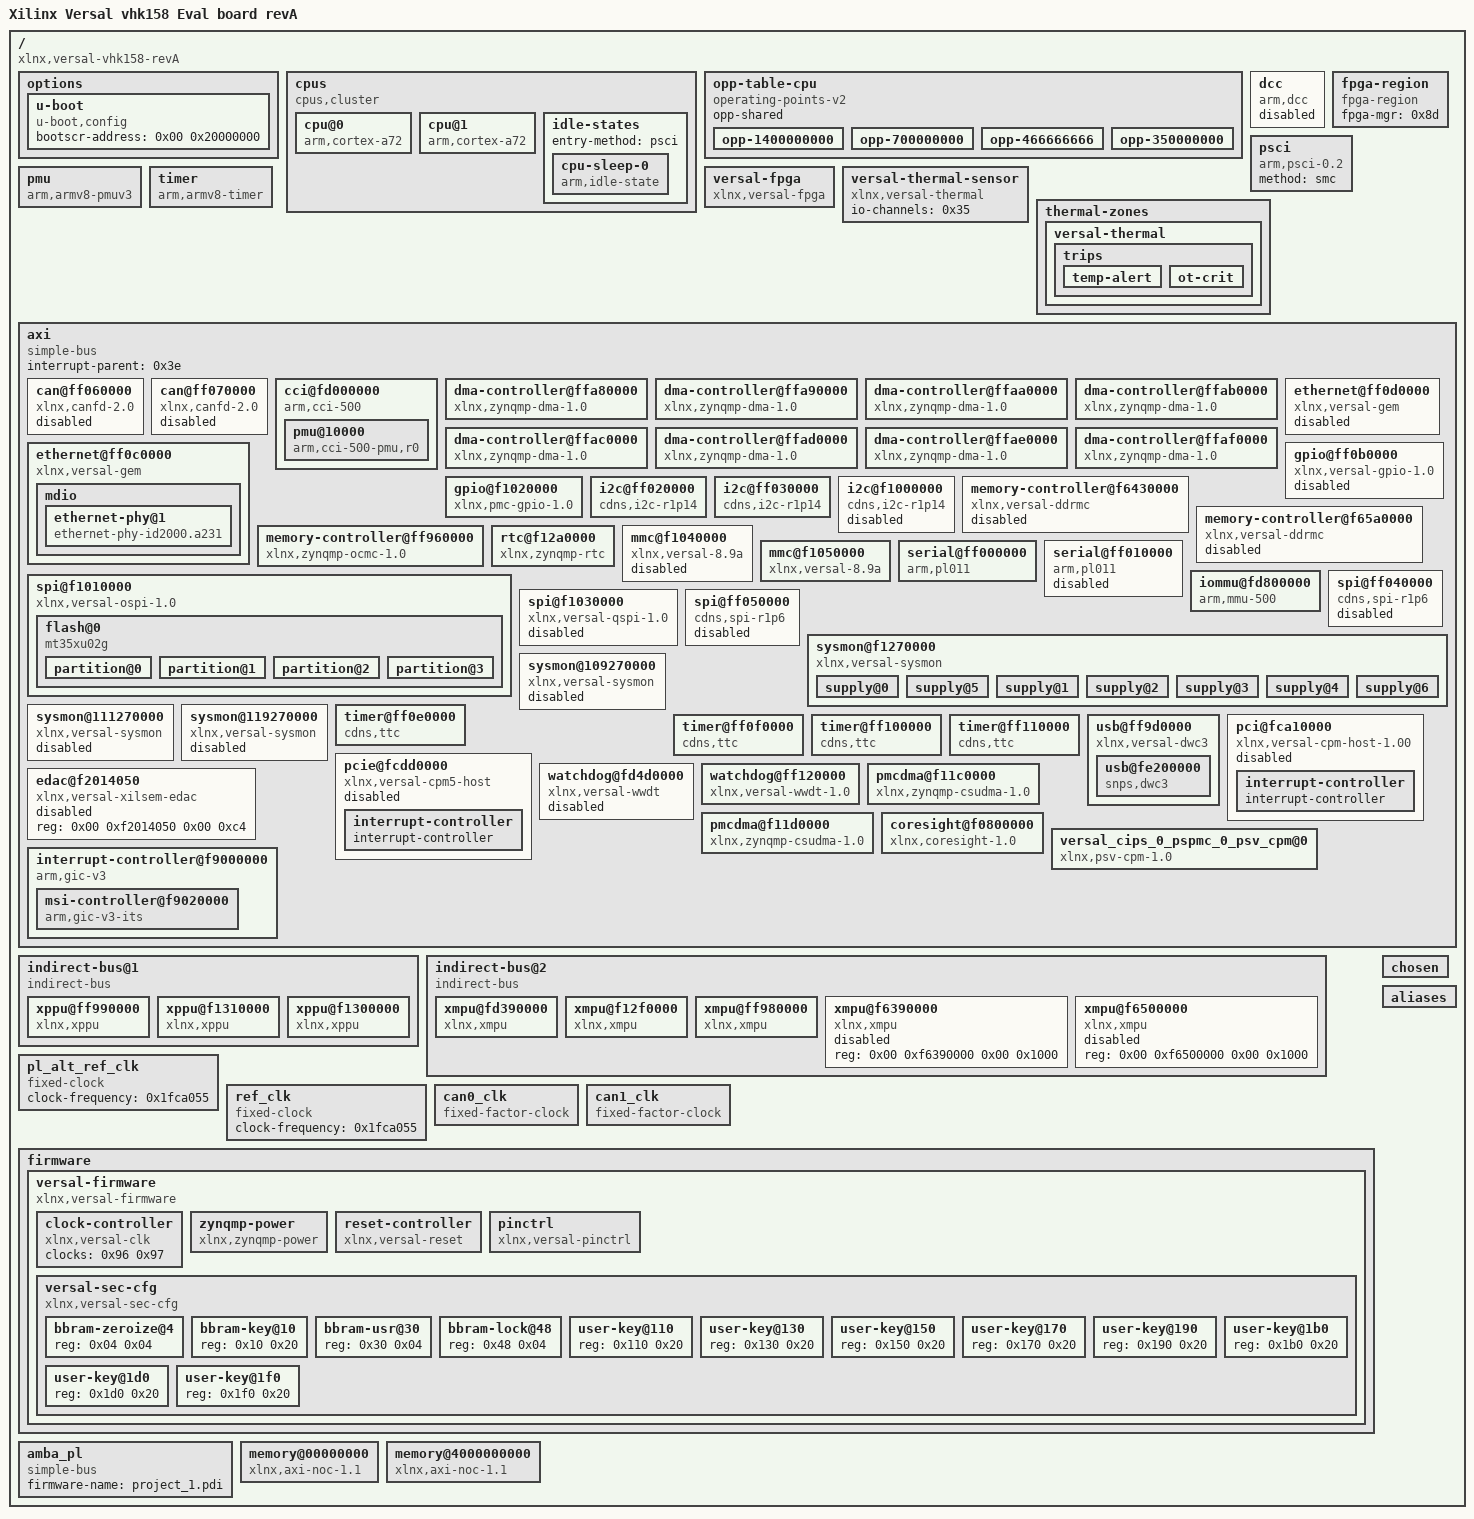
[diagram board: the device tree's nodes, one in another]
/dts-v1/;

/ {
	compatible = "xlnx,versal-vhk158-revA\0xlnx,versal-vhk158\0xlnx,versal";
	#address-cells = <0x02>;
	#size-cells = <0x02>;
	model = "Xilinx Versal vhk158 Eval board revA";
	board = "vhk158";
	device_id = "xcvh1582";
	slrcount = <0x02>;
	family = "Versal";

	options {

		u-boot {
			compatible = "u-boot,config";
			bootscr-address = <0x00 0x20000000>;
		};
	};

	cpus {
		#address-cells = <0x01>;
		#size-cells = <0x00>;
		compatible = "cpus,cluster";
		#ranges-address-cells = <0x02>;
		#ranges-size-cells = <0x02>;
		phandle = <0x98>;

		cpu@0 {
			compatible = "arm,cortex-a72\0arm,armv8";
			device_type = "cpu";
			enable-method = "psci";
			operating-points-v2 = <0x6f>;
			reg = <0x00>;
			cpu-idle-states = <0x70>;
			power-domains = <0x71 0x18110003>;
			clocks = <0x72 0x4d>;
			xlnx,timestamp-clk-freq = <0x5f5dd19>;
			xlnx,pss-ref-clk-freq = <0x1fc9f08>;
			stamp-frequency = <0x5f5dd19>;
			xlnx,ip-name = "psv_cortexa72";
			xlnx,cpu-clk-freq-hz = <0x5372172a>;
			cpu-frequency = <0x5372172a>;
			bus-handle = <0x01>;
			phandle = <0x99>;
		};

		cpu@1 {
			compatible = "arm,cortex-a72\0arm,armv8";
			device_type = "cpu";
			enable-method = "psci";
			operating-points-v2 = <0x6f>;
			reg = <0x01>;
			cpu-idle-states = <0x70>;
			power-domains = <0x71 0x18110004>;
			xlnx,timestamp-clk-freq = <0x5f5dd19>;
			xlnx,pss-ref-clk-freq = <0x1fc9f08>;
			stamp-frequency = <0x5f5dd19>;
			xlnx,ip-name = "psv_cortexa72";
			xlnx,cpu-clk-freq-hz = <0x5372172a>;
			cpu-frequency = <0x5372172a>;
			bus-handle = <0x01>;
			phandle = <0x9a>;
		};

		idle-states {
			entry-method = "psci";

			cpu-sleep-0 {
				compatible = "arm,idle-state";
				arm,psci-suspend-param = <0x40000000>;
				local-timer-stop;
				entry-latency-us = <0x12c>;
				exit-latency-us = <0x258>;
				min-residency-us = <0x2710>;
				phandle = <0x70>;
			};
		};
	};

	opp-table-cpu {
		compatible = "operating-points-v2";
		opp-shared;
		phandle = <0x6f>;

		opp-1400000000 {
			opp-hz = <0x00 0x53724e00>;
			clock-latency-ns = <0x7a120>;
			opp-microvolt = <0xf4240>;
		};

		opp-700000000 {
			opp-hz = <0x00 0x29b92700>;
			clock-latency-ns = <0x7a120>;
			opp-microvolt = <0xf4240>;
		};

		opp-466666666 {
			opp-hz = <0x00 0x1bd0c4aa>;
			clock-latency-ns = <0x7a120>;
			opp-microvolt = <0xf4240>;
		};

		opp-350000000 {
			opp-hz = <0x00 0x14dc9380>;
			clock-latency-ns = <0x7a120>;
			opp-microvolt = <0xf4240>;
		};
	};

	dcc {
		compatible = "arm,dcc";
		status = "disabled";
		bootph-all;
		phandle = <0xa3>;
	};

	fpga-region {
		compatible = "fpga-region";
		fpga-mgr = <0x8d>;
		#address-cells = <0x02>;
		#size-cells = <0x02>;
		phandle = <0xa4>;
	};

	psci {
		compatible = "arm,psci-0.2";
		method = "smc";
		phandle = <0xa5>;
	};

	pmu {
		compatible = "arm,armv8-pmuv3";
		interrupt-parent = <0x3e>;
		interrupts = <0x01 0x07 0x304>;
	};

	timer {
		compatible = "arm,armv8-timer";
		interrupt-parent = <0x3e>;
		interrupts = <0x01 0x0d 0x04 0x01 0x0e 0x04 0x01 0x0b 0x04 0x01 0x0a 0x04>;
		phandle = <0xa6>;
	};

	versal-fpga {
		compatible = "xlnx,versal-fpga";
		phandle = <0x8d>;
	};

	versal-thermal-sensor {
		compatible = "xlnx,versal-thermal";
		#thermal-sensor-cells = <0x00>;
		io-channels = <0x35>;
		io-channel-names = "sysmon-temp-channel";
		phandle = <0x8f>;
	};

	thermal-zones {

		versal-thermal {
			polling-delay-passive = <0xfa>;
			polling-delay = <0x3e8>;
			thermal-sensors = <0x8f>;
			phandle = <0xa7>;

			trips {

				temp-alert {
					temperature = <0x11170>;
					hysteresis = <0x00>;
					type = "passive";
					phandle = <0xa8>;
				};

				ot-crit {
					temperature = <0x1e848>;
					hysteresis = <0x00>;
					type = "critical";
					phandle = <0xa9>;
				};
			};
		};
	};

	axi {
		compatible = "simple-bus";
		#address-cells = <0x02>;
		#size-cells = <0x02>;
		ranges;
		interrupt-parent = <0x3e>;
		bootph-all;
		phandle = <0x01>;

		can@ff060000 {
			compatible = "xlnx,canfd-2.0";
			status = "disabled";
			reg = <0x00 0xff060000 0x00 0x6000>;
			interrupts = <0x00 0x14 0x04>;
			interrupt-parent = <0x3e>;
			clock-names = "can_clk\0s_axi_aclk";
			rx-fifo-depth = <0x40>;
			tx-mailbox-count = <0x20>;
			clocks = <0x90 0x72 0x52>;
			power-domains = <0x71 0x1822401f>;
			phandle = <0xaa>;
		};

		can@ff070000 {
			compatible = "xlnx,canfd-2.0";
			status = "disabled";
			reg = <0x00 0xff070000 0x00 0x6000>;
			interrupts = <0x00 0x15 0x04>;
			interrupt-parent = <0x3e>;
			clock-names = "can_clk\0s_axi_aclk";
			rx-fifo-depth = <0x40>;
			tx-mailbox-count = <0x20>;
			clocks = <0x91 0x72 0x52>;
			power-domains = <0x71 0x18224020>;
			phandle = <0xab>;
		};

		cci@fd000000 {
			compatible = "arm,cci-500";
			status = "okay";
			reg = <0x00 0xfd000000 0x00 0x10000>;
			ranges = <0x00 0x00 0xfd000000 0xa0000>;
			#address-cells = <0x01>;
			#size-cells = <0x01>;
			xlnx,ip-name = "psv_fpd_maincci";
			phandle = <0x40>;

			pmu@10000 {
				compatible = "arm,cci-500-pmu,r0";
				reg = <0x10000 0x90000>;
				interrupt-parent = <0x3e>;
				interrupts = <0x00 0x6a 0x04 0x00 0x6a 0x04 0x00 0x6a 0x04 0x00 0x6a 0x04 0x00 0x6a 0x04 0x00 0x6a 0x04 0x00 0x6a 0x04 0x00 0x6a 0x04>;
				phandle = <0xac>;
			};
		};

		dma-controller@ffa80000 {
			compatible = "xlnx,zynqmp-dma-1.0";
			status = "okay";
			reg = <0x00 0xffa80000 0x00 0x1000>;
			interrupts = <0x00 0x3c 0x04>;
			interrupt-parent = <0x3e>;
			clock-names = "clk_main\0clk_apb";
			xlnx,dma-type = <0x01>;
			#dma-cells = <0x01>;
			xlnx,bus-width = <0x40>;
			clocks = <0x72 0x51 0x72 0x52>;
			power-domains = <0x71 0x18224035>;
			xlnx,is-cache-coherent = <0x00>;
			xlnx,ip-name = "psv_adma";
			xlnx,dma-mode = <0x01>;
			phandle = <0x63>;
		};

		dma-controller@ffa90000 {
			compatible = "xlnx,zynqmp-dma-1.0";
			status = "okay";
			reg = <0x00 0xffa90000 0x00 0x1000>;
			interrupts = <0x00 0x3d 0x04>;
			interrupt-parent = <0x3e>;
			clock-names = "clk_main\0clk_apb";
			xlnx,dma-type = <0x01>;
			#dma-cells = <0x01>;
			xlnx,bus-width = <0x40>;
			clocks = <0x72 0x51 0x72 0x52>;
			power-domains = <0x71 0x18224036>;
			xlnx,is-cache-coherent = <0x00>;
			xlnx,ip-name = "psv_adma";
			xlnx,dma-mode = <0x01>;
			phandle = <0x64>;
		};

		dma-controller@ffaa0000 {
			compatible = "xlnx,zynqmp-dma-1.0";
			status = "okay";
			reg = <0x00 0xffaa0000 0x00 0x1000>;
			interrupts = <0x00 0x3e 0x04>;
			interrupt-parent = <0x3e>;
			clock-names = "clk_main\0clk_apb";
			xlnx,dma-type = <0x01>;
			#dma-cells = <0x01>;
			xlnx,bus-width = <0x40>;
			clocks = <0x72 0x51 0x72 0x52>;
			power-domains = <0x71 0x18224037>;
			xlnx,is-cache-coherent = <0x00>;
			xlnx,ip-name = "psv_adma";
			xlnx,dma-mode = <0x01>;
			phandle = <0x65>;
		};

		dma-controller@ffab0000 {
			compatible = "xlnx,zynqmp-dma-1.0";
			status = "okay";
			reg = <0x00 0xffab0000 0x00 0x1000>;
			interrupts = <0x00 0x3f 0x04>;
			interrupt-parent = <0x3e>;
			clock-names = "clk_main\0clk_apb";
			xlnx,dma-type = <0x01>;
			#dma-cells = <0x01>;
			xlnx,bus-width = <0x40>;
			clocks = <0x72 0x51 0x72 0x52>;
			power-domains = <0x71 0x18224038>;
			xlnx,is-cache-coherent = <0x00>;
			xlnx,ip-name = "psv_adma";
			xlnx,dma-mode = <0x01>;
			phandle = <0x66>;
		};

		dma-controller@ffac0000 {
			compatible = "xlnx,zynqmp-dma-1.0";
			status = "okay";
			reg = <0x00 0xffac0000 0x00 0x1000>;
			interrupts = <0x00 0x40 0x04>;
			interrupt-parent = <0x3e>;
			clock-names = "clk_main\0clk_apb";
			xlnx,dma-type = <0x01>;
			#dma-cells = <0x01>;
			xlnx,bus-width = <0x40>;
			clocks = <0x72 0x51 0x72 0x52>;
			power-domains = <0x71 0x18224039>;
			xlnx,is-cache-coherent = <0x00>;
			xlnx,ip-name = "psv_adma";
			xlnx,dma-mode = <0x01>;
			phandle = <0x67>;
		};

		dma-controller@ffad0000 {
			compatible = "xlnx,zynqmp-dma-1.0";
			status = "okay";
			reg = <0x00 0xffad0000 0x00 0x1000>;
			interrupts = <0x00 0x41 0x04>;
			interrupt-parent = <0x3e>;
			clock-names = "clk_main\0clk_apb";
			xlnx,dma-type = <0x01>;
			#dma-cells = <0x01>;
			xlnx,bus-width = <0x40>;
			clocks = <0x72 0x51 0x72 0x52>;
			power-domains = <0x71 0x1822403a>;
			xlnx,is-cache-coherent = <0x00>;
			xlnx,ip-name = "psv_adma";
			xlnx,dma-mode = <0x01>;
			phandle = <0x68>;
		};

		dma-controller@ffae0000 {
			compatible = "xlnx,zynqmp-dma-1.0";
			status = "okay";
			reg = <0x00 0xffae0000 0x00 0x1000>;
			interrupts = <0x00 0x42 0x04>;
			interrupt-parent = <0x3e>;
			clock-names = "clk_main\0clk_apb";
			xlnx,dma-type = <0x01>;
			#dma-cells = <0x01>;
			xlnx,bus-width = <0x40>;
			clocks = <0x72 0x51 0x72 0x52>;
			power-domains = <0x71 0x1822403b>;
			xlnx,is-cache-coherent = <0x00>;
			xlnx,ip-name = "psv_adma";
			xlnx,dma-mode = <0x01>;
			phandle = <0x69>;
		};

		dma-controller@ffaf0000 {
			compatible = "xlnx,zynqmp-dma-1.0";
			status = "okay";
			reg = <0x00 0xffaf0000 0x00 0x1000>;
			interrupts = <0x00 0x43 0x04>;
			interrupt-parent = <0x3e>;
			clock-names = "clk_main\0clk_apb";
			xlnx,dma-type = <0x01>;
			#dma-cells = <0x01>;
			xlnx,bus-width = <0x40>;
			clocks = <0x72 0x51 0x72 0x52>;
			power-domains = <0x71 0x1822403c>;
			xlnx,is-cache-coherent = <0x00>;
			xlnx,ip-name = "psv_adma";
			xlnx,dma-mode = <0x01>;
			phandle = <0x6a>;
		};

		ethernet@ff0c0000 {
			compatible = "xlnx,versal-gem\0cdns,gem";
			status = "okay";
			reg = <0x00 0xff0c0000 0x00 0x1000>;
			interrupts = <0x00 0x38 0x04 0x00 0x38 0x04>;
			interrupt-parent = <0x3e>;
			clock-names = "pclk\0hclk\0tx_clk\0rx_clk\0tsu_clk";
			#address-cells = <0x01>;
			#size-cells = <0x00>;
			clocks = <0x72 0x52 0x72 0x58 0x72 0x31 0x72 0x30 0x72 0x2b>;
			power-domains = <0x71 0x18224019>;
			xlnx,has-mdio = <0x01>;
			xlnx,is-cache-coherent = <0x00>;
			xlnx,gem-board-interface = "custom";
			phy-mode = "rgmii-id";
			xlnx,enet-slcr-1000mbps-div0 = <0x02>;
			xlnx,enet-slcr-10mbps-div0 = <0x64>;
			xlnx,enet-tsu-clk-freq-hz = <0xee6a8ba>;
			xlnx,ip-name = "psv_ethernet";
			xlnx,eth-mode = <0x01>;
			xlnx,enet-clk-freq-hz = <0x773545d>;
			xlnx,enet-slcr-100mbps-div0 = <0x0a>;
			local-mac-address = [ff ff ff ff ff ff];
			phy-handle = <0x92>;
			phandle = <0x52>;

			mdio {
				#address-cells = <0x01>;
				#size-cells = <0x00>;
				phandle = <0xad>;

				ethernet-phy@1 {
					#phy-cells = <0x01>;
					compatible = "ethernet-phy-id2000.a231";
					reg = <0x01>;
					ti,rx-internal-delay = <0x0b>;
					ti,tx-internal-delay = <0x0a>;
					ti,fifo-depth = <0x01>;
					ti,dp83867-rxctrl-strap-quirk;
					reset-assert-us = <0x64>;
					reset-deassert-us = <0x118>;
					reset-gpios = <0x27 0x30 0x01>;
					phandle = <0x92>;
				};
			};
		};

		ethernet@ff0d0000 {
			compatible = "xlnx,versal-gem\0cdns,gem";
			status = "disabled";
			reg = <0x00 0xff0d0000 0x00 0x1000>;
			interrupts = <0x00 0x3a 0x04 0x00 0x3a 0x04>;
			interrupt-parent = <0x3e>;
			clock-names = "pclk\0hclk\0tx_clk\0rx_clk\0tsu_clk";
			#address-cells = <0x01>;
			#size-cells = <0x00>;
			clocks = <0x72 0x52 0x72 0x59 0x72 0x33 0x72 0x32 0x72 0x2b>;
			power-domains = <0x71 0x1822401a>;
			phandle = <0xae>;
		};

		gpio@ff0b0000 {
			compatible = "xlnx,versal-gpio-1.0";
			status = "disabled";
			reg = <0x00 0xff0b0000 0x00 0x1000>;
			interrupts = <0x00 0x0d 0x04>;
			interrupt-parent = <0x3e>;
			#gpio-cells = <0x02>;
			gpio-controller;
			#interrupt-cells = <0x02>;
			interrupt-controller;
			clocks = <0x72 0x52>;
			power-domains = <0x71 0x18224023>;
			phandle = <0xaf>;
		};

		gpio@f1020000 {
			compatible = "xlnx,pmc-gpio-1.0";
			status = "okay";
			reg = <0x00 0xf1020000 0x00 0x1000>;
			interrupts = <0x00 0x7a 0x04>;
			interrupt-parent = <0x3e>;
			#gpio-cells = <0x02>;
			gpio-controller;
			#interrupt-cells = <0x02>;
			interrupt-controller;
			clocks = <0x72 0x3d>;
			power-domains = <0x71 0x1822402c>;
			xlnx,ip-name = "psv_pmc_gpio";
			phandle = <0x27>;
		};

		i2c@ff020000 {
			compatible = "cdns,i2c-r1p14";
			status = "okay";
			reg = <0x00 0xff020000 0x00 0x1000>;
			interrupts = <0x00 0x0e 0x04>;
			interrupt-parent = <0x3e>;
			clock-frequency = <0x186a0>;
			#address-cells = <0x01>;
			#size-cells = <0x00>;
			clocks = <0x72 0x62>;
			power-domains = <0x71 0x1822401d>;
			xlnx,clock-freq = <0x5f5dd19>;
			xlnx,i2c-clk-freq-hz = <0x5f5dd19>;
			xlnx,ip-name = "psv_i2c";
			xlnx,iic-board-interface = "custom";
			phandle = <0x4e>;
		};

		i2c@ff030000 {
			compatible = "cdns,i2c-r1p14";
			status = "okay";
			reg = <0x00 0xff030000 0x00 0x1000>;
			interrupts = <0x00 0x0f 0x04>;
			interrupt-parent = <0x3e>;
			clock-frequency = <0x186a0>;
			#address-cells = <0x01>;
			#size-cells = <0x00>;
			clocks = <0x72 0x63>;
			power-domains = <0x71 0x1822401e>;
			xlnx,clock-freq = <0x5f5dd19>;
			xlnx,i2c-clk-freq-hz = <0x5f5dd19>;
			xlnx,ip-name = "psv_i2c";
			xlnx,iic-board-interface = "custom";
			phandle = <0x4f>;
		};

		i2c@f1000000 {
			compatible = "cdns,i2c-r1p14";
			status = "disabled";
			reg = <0x00 0xf1000000 0x00 0x1000>;
			interrupts = <0x00 0x7b 0x04>;
			interrupt-parent = <0x3e>;
			clock-frequency = <0x186a0>;
			#address-cells = <0x01>;
			#size-cells = <0x00>;
			clocks = <0x72 0x3e>;
			power-domains = <0x71 0x1822402d>;
			phandle = <0xb0>;
		};

		memory-controller@f6430000 {
			compatible = "xlnx,versal-ddrmc";
			status = "disabled";
			reg = <0x00 0xf6430000 0x00 0x2000 0x00 0xf6380000 0x00 0x20000>;
			reg-names = "base\0noc";
			interrupts = <0x00 0x93 0x04>;
			interrupt-parent = <0x3e>;
			phandle = <0xb3>;
		};

		memory-controller@f65a0000 {
			compatible = "xlnx,versal-ddrmc";
			status = "disabled";
			reg = <0x00 0xf65a0000 0x00 0x2000 0x00 0xf64f0000 0x00 0x20000>;
			reg-names = "base\0noc";
			interrupts = <0x00 0x93 0x04>;
			interrupt-parent = <0x3e>;
			phandle = <0xb4>;
		};

		memory-controller@ff960000 {
			compatible = "xlnx,zynqmp-ocmc-1.0";
			reg = <0x00 0xff960000 0x00 0x1000>;
			interrupts = <0x00 0x0a 0x04>;
			interrupt-parent = <0x3e>;
			phandle = <0xb5>;
		};

		rtc@f12a0000 {
			compatible = "xlnx,zynqmp-rtc";
			status = "okay";
			reg = <0x00 0xf12a0000 0x00 0x100>;
			interrupt-names = "alarm\0sec";
			interrupts = <0x00 0x8e 0x04 0x00 0x8f 0x04>;
			interrupt-parent = <0x3e>;
			calibration = <0x7fff>;
			power-domains = <0x71 0x18224034>;
			xlnx,ip-name = "psv_pmc_rtc";
			phandle = <0x36>;
		};

		mmc@f1040000 {
			compatible = "xlnx,versal-8.9a\0arasan,sdhci-8.9a";
			status = "disabled";
			reg = <0x00 0xf1040000 0x00 0x10000>;
			interrupts = <0x00 0x7e 0x04>;
			interrupt-parent = <0x3e>;
			clock-names = "clk_xin\0clk_ahb\0gate";
			#clock-cells = <0x01>;
			clock-output-names = "clk_out_sd0\0clk_in_sd0";
			clocks = <0x72 0x3b 0x72 0x52 0x72 0x4a>;
			power-domains = <0x71 0x1822402e>;
			phandle = <0xb6>;
		};

		mmc@f1050000 {
			compatible = "xlnx,versal-8.9a\0arasan,sdhci-8.9a";
			status = "okay";
			reg = <0x00 0xf1050000 0x00 0x10000>;
			interrupts = <0x00 0x80 0x04>;
			interrupt-parent = <0x3e>;
			clock-names = "clk_xin\0clk_ahb\0gate";
			#clock-cells = <0x01>;
			clock-output-names = "clk_out_sd1\0clk_in_sd1";
			clocks = <0x72 0x3c 0x72 0x52 0x72 0x4a>;
			power-domains = <0x71 0x1822402f>;
			xlnx,sd-board-interface = "custom";
			xlnx,is-cache-coherent = <0x00>;
			xlnx,clk-50-ddr-otap-dly = <0x03>;
			xlnx,clk-50-sdr-itap-dly = <0x25>;
			xlnx,has-emio = <0x00>;
			clock-frequency = <0xbebba31>;
			xlnx,clk-100-sdr-otap-dly = <0x03>;
			xlnx,mio-bank = <0x01>;
			xlnx,ip-name = "psv_pmc_sd";
			xlnx,bus-width = <0x08>;
			xlnx,card-detect = <0x01>;
			xlnx,has-wp = <0x00>;
			xlnx,has-cd = <0x01>;
			xlnx,slot-type = <0x04>;
			xlnx,clk-50-sdr-otap-dly = <0x04>;
			xlnx,clk-50-ddr-itap-dly = <0x2a>;
			xlnx,has-power = <0x01>;
			xlnx,clk-200-sdr-otap-dly = <0x02>;
			xlnx,sdio-clk-freq-hz = <0xbebba31>;
			xlnx,write-protect = <0x00>;
			no-1-8-v;
			phandle = <0x28>;
		};

		serial@ff000000 {
			compatible = "arm,pl011\0arm,primecell";
			status = "okay";
			reg = <0x00 0xff000000 0x00 0x1000>;
			interrupts = <0x00 0x12 0x04>;
			interrupt-parent = <0x3e>;
			reg-io-width = <0x04>;
			clock-names = "uartclk\0apb_pclk";
			bootph-all;
			clocks = <0x72 0x5c 0x72 0x52>;
			power-domains = <0x71 0x18224021>;
			xlnx,has-modem = <0x00>;
			xlnx,uart-clk-freq-hz = <0x5f5dd19>;
			port-number = <0x00>;
			xlnx,ip-name = "psv_sbsauart";
			xlnx,uart-board-interface = "custom";
			xlnx,baudrate = <0x1c200>;
			cts-override;
			u-boot,dm-pre-reloc;
			xlnx,clock-freq = <0x5f5dd19>;
			phandle = <0x4d>;
		};

		serial@ff010000 {
			compatible = "arm,pl011\0arm,primecell";
			status = "disabled";
			reg = <0x00 0xff010000 0x00 0x1000>;
			interrupts = <0x00 0x13 0x04>;
			interrupt-parent = <0x3e>;
			reg-io-width = <0x04>;
			clock-names = "uartclk\0apb_pclk";
			bootph-all;
			clocks = <0x72 0x5d 0x72 0x52>;
			power-domains = <0x71 0x18224022>;
			phandle = <0xb7>;
		};

		iommu@fd800000 {
			compatible = "arm,mmu-500";
			status = "okay";
			reg = <0x00 0xfd800000 0x00 0x40000>;
			stream-match-mask = <0x7c00>;
			#iommu-cells = <0x01>;
			#global-interrupts = <0x01>;
			interrupts = <0x00 0x6b 0x04 0x00 0x6b 0x04 0x00 0x6b 0x04 0x00 0x6b 0x04 0x00 0x6b 0x04 0x00 0x6b 0x04 0x00 0x6b 0x04 0x00 0x6b 0x04 0x00 0x6b 0x04 0x00 0x6b 0x04 0x00 0x6b 0x04 0x00 0x6b 0x04 0x00 0x6b 0x04 0x00 0x6b 0x04 0x00 0x6b 0x04 0x00 0x6b 0x04 0x00 0x6b 0x04 0x00 0x6b 0x04 0x00 0x6b 0x04 0x00 0x6b 0x04 0x00 0x6b 0x04 0x00 0x6b 0x04 0x00 0x6b 0x04 0x00 0x6b 0x04 0x00 0x6b 0x04 0x00 0x6b 0x04 0x00 0x6b 0x04 0x00 0x6b 0x04 0x00 0x6b 0x04 0x00 0x6b 0x04 0x00 0x6b 0x04 0x00 0x6b 0x04 0x00 0x6b 0x04>;
			interrupt-parent = <0x3e>;
			xlnx,ip-name = "psv_fpd_smmutcu";
			phandle = <0x4b>;
		};

		spi@f1010000 {
			compatible = "xlnx,versal-ospi-1.0\0cdns,qspi-nor";
			status = "okay";
			reg = <0x00 0xf1010000 0x00 0x10000 0x00 0xc0000000 0x00 0x20000000>;
			interrupts = <0x00 0x7c 0x04>;
			interrupt-parent = <0x3e>;
			cdns,fifo-depth = <0x100>;
			cdns,fifo-width = <0x04>;
			cdns,is-dma = <0x01>;
			cdns,trigger-address = <0xc0000000>;
			#address-cells = <0x01>;
			#size-cells = <0x00>;
			clocks = <0x72 0x3a>;
			power-domains = <0x71 0x1822402a>;
			reset-names = "qspi";
			resets = <0x93 0xc10402e>;
			is-stacked = <0x00>;
			xlnx,is-cache-coherent = <0x00>;
			xlnx,clock-freq = <0xbebba31>;
			xlnx,ip-name = "psv_pmc_ospi";
			xlnx,ospi-clk-freq-hz = <0xbebba31>;
			is-dual = <0x00>;
			xlnx,ospi-mode = <0x00>;
			bus-num = <0x02>;
			num-cs = <0x01>;
			phandle = <0x26>;

			flash@0 {
				compatible = "mt35xu02g\0micron,m25p80\0jedec,spi-nor";
				reg = <0x00>;
				#address-cells = <0x01>;
				#size-cells = <0x01>;
				cdns,read-delay = <0x00>;
				cdns,tshsl-ns = <0x00>;
				cdns,tsd2d-ns = <0x00>;
				cdns,tchsh-ns = <0x01>;
				cdns,tslch-ns = <0x01>;
				spi-tx-bus-width = <0x08>;
				spi-rx-bus-width = <0x08>;
				spi-max-frequency = <0x1312d00>;
				no-wp;
				reset-gpios = <0x27 0x0c 0x01>;
				phandle = <0x02>;

				partition@0 {
					label = "spi0-boot";
					reg = <0x00 0x40000>;
				};

				partition@1 {
					label = "spi0-bootenv";
					reg = <0x40000 0x20000>;
				};

				partition@2 {
					label = "spi0-config";
					reg = <0x60000 0x20000>;
				};

				partition@3 {
					label = "spi0-kernel";
					reg = <0x80000 0xc00000>;
				};
			};
		};

		spi@f1030000 {
			compatible = "xlnx,versal-qspi-1.0";
			status = "disabled";
			reg = <0x00 0xf1030000 0x00 0x1000>;
			interrupts = <0x00 0x7d 0x04>;
			interrupt-parent = <0x3e>;
			clock-names = "ref_clk\0pclk";
			#address-cells = <0x01>;
			#size-cells = <0x00>;
			clocks = <0x72 0x39 0x72 0x52>;
			power-domains = <0x71 0x1822402b>;
			phandle = <0xb8>;
		};

		spi@ff040000 {
			compatible = "cdns,spi-r1p6";
			status = "disabled";
			reg = <0x00 0xff040000 0x00 0x1000>;
			interrupts = <0x00 0x10 0x04>;
			interrupt-parent = <0x3e>;
			clock-names = "ref_clk\0pclk";
			#address-cells = <0x01>;
			#size-cells = <0x00>;
			clocks = <0x72 0x5e 0x72 0x52>;
			power-domains = <0x71 0x1822401b>;
			phandle = <0xb9>;
		};

		spi@ff050000 {
			compatible = "cdns,spi-r1p6";
			status = "disabled";
			reg = <0x00 0xff050000 0x00 0x1000>;
			interrupts = <0x00 0x11 0x04>;
			interrupt-parent = <0x3e>;
			clock-names = "ref_clk\0pclk";
			#address-cells = <0x01>;
			#size-cells = <0x00>;
			clocks = <0x72 0x5f 0x72 0x52>;
			power-domains = <0x71 0x1822401c>;
			phandle = <0xba>;
		};

		sysmon@f1270000 {
			compatible = "xlnx,versal-sysmon";
			#io-channel-cells = <0x00>;
			reg = <0x00 0xf1270000 0x00 0x4000>;
			interrupts = <0x00 0x90 0x04>;
			xlnx,numchannels = [07];
			#address-cells = <0x02>;
			#size-cells = <0x02>;
			xlnx,nodeid = <0x18224055>;
			xlnx,sat-63-desc = "PS , FPD , satellite";
			xlnx,sat-1-desc = "PMC , system , ADC";
			xlnx,sat-17-x = <0x351d>;
			xlnx,sat-9-x = <0x6e0c>;
			xlnx,sat-20-desc = "HBM , Satellite , (right)";
			xlnx,sat-19-desc = "VNOC , satellite";
			xlnx,sat-17-y = <0x3efd>;
			xlnx,sat-9-y = <0x4ebb>;
			xlnx,sat-22-x = <0x20df>;
			xlnx,meas-0-root-id = <0x00>;
			xlnx,sat-22-y = <0x4af0>;
			xlnx,meas-1-root-id = <0x05>;
			xlnx,ip-name = "psv_pmc_sysmon";
			xlnx,meas-2-root-id = <0x01>;
			xlnx,sat-16-desc = "HBM , Satellite , (left)";
			xlnx,meas-2-slr-number = <0x00>;
			xlnx,meas-3-root-id = <0x02>;
			xlnx,sat-9-desc = "Clocking , column , satellite";
			xlnx,sat-26-x = <0xe8e>;
			xlnx,meas-4-root-id = <0x03>;
			xlnx,sat-28-desc = "Clocking , column , satellite";
			xlnx,sat-26-y = <0x5480>;
			xlnx,meas-5-root-id = <0x04>;
			xlnx,sat-10-x = <0x6e0c>;
			xlnx,sat-64-x = <0x4a3>;
			xlnx,sat-2-x = <0x4a3>;
			xlnx,meas-6-root-id = <0x06>;
			xlnx,sat-10-y = <0x488c>;
			xlnx,sat-64-y = <0xe49>;
			xlnx,sat-2-y = <0x3c2b>;
			xlnx,sat-13-desc = "VNOC , satellite";
			xlnx,sat-6-desc = "HBM , Satellite , (right)";
			xlnx,sat-14-x = <0x495b>;
			xlnx,sat-6-x = <0x5eb2>;
			xlnx,sat-25-desc = "Clocking , column , satellite";
			xlnx,sat-14-y = <0x4af0>;
			xlnx,sat-6-y = <0x6f0e>;
			xlnx,sat-10-desc = "Clocking , column , satellite";
			xlnx,sat-18-x = <0x351d>;
			xlnx,sat-3-desc = "VNOC , satellite";
			xlnx,sat-18-y = <0x4af0>;
			xlnx,meas-5-slr-number = <0x00>;
			xlnx,sat-22-desc = "VNOC , satellite";
			xlnx,sat-23-x = <0x20df>;
			xlnx,meas-0-slr-number = <0x00>;
			xlnx,sat-23-y = <0x56e4>;
			xlnx,sat-18-desc = "VNOC , satellite";
			xlnx,sat-27-x = <0xe8e>;
			xlnx,sat-27-y = <0x4ebb>;
			xlnx,sat-11-x = <0x6e0c>;
			xlnx,sat-3-x = <0x5d99>;
			xlnx,sat-11-y = <0x42c8>;
			xlnx,sat-3-y = <0x3efd>;
			status = "okay";
			xlnx,sat-15-desc = "VNOC , satellite";
			xlnx,sat-15-x = <0x495b>;
			xlnx,sat-8-desc = "Clocking , column , satellite";
			xlnx,sat-7-x = <0x6e0c>;
			xlnx,sat-15-y = <0x56e4>;
			xlnx,sat-7-y = <0x5aaf>;
			xlnx,sat-27-desc = "Clocking , column , satellite";
			xlnx,meas-3-slr-number = <0x00>;
			xlnx,sat-20-x = <0x3379>;
			xlnx,sat-19-x = <0x351d>;
			xlnx,sat-12-desc = "Clocking , column , satellite";
			xlnx,sat-20-y = <0x6f0e>;
			xlnx,sat-19-y = <0x56e4>;
			xlnx,sat-5-desc = "VNOC , satellite";
			xlnx,sat-24-desc = "HBM , Satellite , (left)";
			xlnx,sat-24-x = <0x1de0>;
			xlnx,sat-24-y = <0x6f0e>;
			xlnx,sat-64-desc = "PS , LPD , satellite";
			xlnx,sat-2-desc = "PMC , user , ADC";
			xlnx,sat-28-x = <0xe8e>;
			xlnx,sat-21-desc = "VNOC , satellite";
			xlnx,sat-28-y = <0x488c>;
			xlnx,meas-6-slr-number = <0x00>;
			xlnx,sat-12-x = <0x6e0c>;
			xlnx,sat-4-x = <0x5d99>;
			xlnx,sat-12-y = <0x3c99>;
			xlnx,sat-4-y = <0x4af0>;
			xlnx,meas-1-slr-number = <0x00>;
			xlnx,sat-16-x = <0x4918>;
			xlnx,sat-17-desc = "VNOC , satellite";
			xlnx,sat-8-x = <0x6e0c>;
			xlnx,sat-16-y = <0x6f0e>;
			xlnx,sat-8-y = <0x5480>;
			xlnx,meas-0 = "VCCAUX";
			xlnx,meas-1 = "VCC_SOC";
			xlnx,sat-21-x = <0x20df>;
			xlnx,meas-2 = "VCCAUX_PMC";
			xlnx,sat-21-y = <0x3efd>;
			xlnx,meas-3 = "VCC_PMC";
			xlnx,sat-14-desc = "VNOC , satellite";
			xlnx,meas-4 = "VCC_PSFP";
			xlnx,sat-7-desc = "Clocking , column , satellite";
			xlnx,meas-5 = "VCC_PSLP";
			xlnx,sat-26-desc = "Clocking , column , satellite";
			xlnx,sat-25-x = <0xe8e>;
			xlnx,meas-6 = "VP_VN";
			xlnx,sat-25-y = <0x5aaf>;
			xlnx,sat-63-x = <0x4a3>;
			xlnx,sat-1-x = <0x4a3>;
			xlnx,meas-4-slr-number = <0x00>;
			xlnx,sat-11-desc = "Clocking , column , satellite";
			xlnx,sat-63-y = <0xe49>;
			xlnx,sat-1-y = <0x3c2b>;
			xlnx,sat-4-desc = "VNOC , satellite";
			xlnx,sat-23-desc = "VNOC , satellite";
			xlnx,sat-13-x = <0x495b>;
			xlnx,sat-5-x = <0x5d99>;
			xlnx,sat-13-y = <0x3efd>;
			xlnx,sat-5-y = <0x56e4>;
			phandle = <0x35>;

			supply@0 {
				reg = <0x00>;
				xlnx,name = "vccaux";
			};

			supply@5 {
				reg = <0x05>;
				xlnx,name = "vcc_soc";
			};

			supply@1 {
				reg = <0x01>;
				xlnx,name = "vccaux_pmc";
			};

			supply@2 {
				reg = <0x02>;
				xlnx,name = "vcc_pmc";
			};

			supply@3 {
				reg = <0x03>;
				xlnx,name = "vcc_psfp";
			};

			supply@4 {
				reg = <0x04>;
				xlnx,name = "vcc_pslp";
			};

			supply@6 {
				reg = <0x06>;
				xlnx,name = "vp_vn";
			};
		};

		sysmon@109270000 {
			compatible = "xlnx,versal-sysmon";
			status = "disabled";
			reg = <0x01 0x9270000 0x00 0x4000>;
			xlnx,numchannels = [00];
			#address-cells = <0x01>;
			#size-cells = <0x00>;
			xlnx,nodeid = <0x18225055>;
			phandle = <0xbb>;
		};

		sysmon@111270000 {
			compatible = "xlnx,versal-sysmon";
			status = "disabled";
			reg = <0x01 0x11270000 0x00 0x4000>;
			xlnx,numchannels = [00];
			#address-cells = <0x01>;
			#size-cells = <0x00>;
			xlnx,nodeid = <0x18226055>;
			phandle = <0xbc>;
		};

		sysmon@119270000 {
			compatible = "xlnx,versal-sysmon";
			status = "disabled";
			reg = <0x01 0x19270000 0x00 0x4000>;
			xlnx,numchannels = [00];
			#address-cells = <0x01>;
			#size-cells = <0x00>;
			xlnx,nodeid = <0x18227055>;
			phandle = <0xbd>;
		};

		timer@ff0e0000 {
			compatible = "cdns,ttc";
			status = "okay";
			interrupts = <0x00 0x25 0x04 0x00 0x26 0x04 0x00 0x27 0x04>;
			interrupt-parent = <0x3e>;
			reg = <0x00 0xff0e0000 0x00 0x1000>;
			timer-width = <0x20>;
			clocks = <0x72 0x27 0x72 0x52>;
			power-domains = <0x71 0x18224024>;
			xlnx,ttc-clk2-clksrc = <0x00>;
			xlnx,ip-name = "psv_ttc";
			xlnx,ttc-clk1-clksrc = <0x00>;
			xlnx,ttc-clk0-freq-hz = <0x8f0cba9>;
			xlnx,ttc-clk1-freq-hz = <0x8f0cba9>;
			xlnx,ttc-clk2-freq-hz = <0x8f0cba9>;
			xlnx,ttc-board-interface = "custom";
			xlnx,clock-freq = <0x8f0cba9>;
			xlnx,ttc-clk0-clksrc = <0x00>;
			phandle = <0x53>;
		};

		timer@ff0f0000 {
			compatible = "cdns,ttc";
			status = "okay";
			interrupts = <0x00 0x28 0x04 0x00 0x29 0x04 0x00 0x2a 0x04>;
			interrupt-parent = <0x3e>;
			reg = <0x00 0xff0f0000 0x00 0x1000>;
			timer-width = <0x20>;
			clocks = <0x72 0x28 0x72 0x52>;
			power-domains = <0x71 0x18224025>;
			xlnx,ttc-clk2-clksrc = <0x00>;
			xlnx,ip-name = "psv_ttc";
			xlnx,ttc-clk1-clksrc = <0x00>;
			xlnx,ttc-clk0-freq-hz = <0x8f0cba9>;
			xlnx,ttc-clk1-freq-hz = <0x8f0cba9>;
			xlnx,ttc-clk2-freq-hz = <0x8f0cba9>;
			xlnx,ttc-board-interface = "custom";
			xlnx,clock-freq = <0x8f0cba9>;
			xlnx,ttc-clk0-clksrc = <0x00>;
			phandle = <0x54>;
		};

		timer@ff100000 {
			compatible = "cdns,ttc";
			status = "okay";
			interrupts = <0x00 0x2b 0x04 0x00 0x2c 0x04 0x00 0x2d 0x04>;
			interrupt-parent = <0x3e>;
			reg = <0x00 0xff100000 0x00 0x1000>;
			timer-width = <0x20>;
			clocks = <0x72 0x29 0x72 0x52>;
			power-domains = <0x71 0x18224026>;
			xlnx,ttc-clk2-clksrc = <0x00>;
			xlnx,ip-name = "psv_ttc";
			xlnx,ttc-clk1-clksrc = <0x00>;
			xlnx,ttc-clk0-freq-hz = <0x8f0cba9>;
			xlnx,ttc-clk1-freq-hz = <0x8f0cba9>;
			xlnx,ttc-clk2-freq-hz = <0x8f0cba9>;
			xlnx,ttc-board-interface = "custom";
			xlnx,clock-freq = <0x8f0cba9>;
			xlnx,ttc-clk0-clksrc = <0x00>;
			phandle = <0x55>;
		};

		timer@ff110000 {
			compatible = "cdns,ttc";
			status = "okay";
			interrupts = <0x00 0x2e 0x04 0x00 0x2f 0x04 0x00 0x30 0x04>;
			interrupt-parent = <0x3e>;
			reg = <0x00 0xff110000 0x00 0x1000>;
			timer-width = <0x20>;
			clocks = <0x72 0x2a 0x72 0x52>;
			power-domains = <0x71 0x18224027>;
			xlnx,ttc-clk2-clksrc = <0x00>;
			xlnx,ip-name = "psv_ttc";
			xlnx,ttc-clk1-clksrc = <0x00>;
			xlnx,ttc-clk0-freq-hz = <0x8f0cba9>;
			xlnx,ttc-clk1-freq-hz = <0x8f0cba9>;
			xlnx,ttc-clk2-freq-hz = <0x8f0cba9>;
			xlnx,ttc-board-interface = "custom";
			xlnx,clock-freq = <0x8f0cba9>;
			xlnx,ttc-clk0-clksrc = <0x00>;
			phandle = <0x56>;
		};

		usb@ff9d0000 {
			compatible = "xlnx,versal-dwc3";
			status = "okay";
			reg = <0x00 0xff9d0000 0x00 0x100>;
			clock-names = "bus_clk\0ref_clk";
			ranges;
			#address-cells = <0x02>;
			#size-cells = <0x02>;
			clocks = <0x72 0x5b 0x72 0x68>;
			power-domains = <0x71 0x18224018>;
			resets = <0x93 0xc104036>;
			xlnx,ip-name = "psv_usb";
			phandle = <0x62>;

			usb@fe200000 {
				compatible = "snps,dwc3";
				status = "okay";
				reg = <0x00 0xfe200000 0x00 0x10000>;
				interrupt-names = "host\0peripheral\0otg\0wakeup";
				interrupts = <0x00 0x16 0x04 0x00 0x16 0x04 0x00 0x1a 0x04 0x00 0x4a 0x04>;
				snps,dis_u2_susphy_quirk;
				snps,dis_u3_susphy_quirk;
				snps,quirk-frame-length-adjustment = <0x20>;
				clock-names = "ref";
				clocks = <0x72 0x5b>;
				xlnx,is-cache-coherent = <0x00>;
				xlnx,ip-name = "psv_usb_xhci";
				dr_mode = "host";
				maximum-speed = "high-speed";
				snps,usb3_lpm_capable;
				phandle = <0x4c>;
			};
		};

		pci@fca10000 {
			device_type = "pci";
			#address-cells = <0x03>;
			#interrupt-cells = <0x01>;
			#size-cells = <0x02>;
			compatible = "xlnx,versal-cpm-host-1.00";
			status = "disabled";
			interrupt-map = <0x00 0x00 0x00 0x01 0x94 0x00 0x00 0x00 0x00 0x02 0x94 0x01 0x00 0x00 0x00 0x03 0x94 0x02 0x00 0x00 0x00 0x04 0x94 0x03>;
			interrupt-map-mask = <0x00 0x00 0x00 0x07>;
			interrupt-names = "misc";
			interrupts = <0x00 0x48 0x04>;
			xlnx,csr-slcr = <0x06 0x00>;
			xlnx,num-of-bars = <0x02>;
			xlnx,port-type = <0x01>;
			interrupt-parent = <0x3e>;
			bus-range = <0x00 0xff>;
			ranges = <0x2000000 0x00 0xe0010000 0x00 0xe0010000 0x00 0x10000000 0x43000000 0x80 0x00 0x80 0x00 0x00 0x80000000>;
			msi-map = <0x00 0x05 0x00 0x10000>;
			reg = <0x06 0x00 0x00 0x1000000 0x00 0xfca10000 0x00 0x1000>;
			reg-names = "cfg\0cpm_slcr";
			phandle = <0xbe>;

			interrupt-controller {
				#address-cells = <0x00>;
				#interrupt-cells = <0x01>;
				interrupt-controller;
				phandle = <0x94>;
			};
		};

		pcie@fcdd0000 {
			device_type = "pci";
			#address-cells = <0x03>;
			#interrupt-cells = <0x01>;
			#size-cells = <0x02>;
			compatible = "xlnx,versal-cpm5-host";
			status = "disabled";
			interrupt-map = <0x00 0x00 0x00 0x01 0x95 0x00 0x00 0x00 0x00 0x02 0x95 0x01 0x00 0x00 0x00 0x03 0x95 0x02 0x00 0x00 0x00 0x04 0x95 0x03>;
			interrupt-map-mask = <0x00 0x00 0x00 0x07>;
			interrupt-names = "misc";
			interrupts = <0x00 0x48 0x04>;
			xlnx,csr-slcr = <0xfce20000>;
			xlnx,num-of-bars = <0x02>;
			xlnx,port-type = <0x01>;
			interrupt-parent = <0x3e>;
			bus-range = <0x00 0xff>;
			ranges = <0x2000000 0x00 0xe0000000 0x00 0xe0000000 0x00 0x10000000 0x43000000 0x80 0x00 0x80 0x00 0x00 0x80000000>;
			msi-map = <0x00 0x05 0x00 0x10000>;
			reg = <0x06 0x00 0x00 0x1000000 0x00 0xfcdd0000 0x00 0x1000 0x00 0xfce20000 0x00 0x1000000>;
			reg-names = "cfg\0cpm_slcr\0cpm_csr";
			phandle = <0xbf>;

			interrupt-controller {
				#address-cells = <0x00>;
				#interrupt-cells = <0x01>;
				interrupt-controller;
				phandle = <0x95>;
			};
		};

		watchdog@fd4d0000 {
			compatible = "xlnx,versal-wwdt";
			status = "disabled";
			reg = <0x00 0xfd4d0000 0x00 0x10000>;
			interrupt-names = "wdt\0wwdt_reset_pending\0gwdt\0gwdt_reset_pending";
			interrupts = <0x00 0x64 0x01 0x00 0x6d 0x01 0x00 0x6c 0x01 0x00 0x6e 0x01>;
			interrupt-parent = <0x3e>;
			timeout-sec = <0x1e>;
			clocks = <0x72 0x4c>;
			power-domains = <0x71 0x18224029>;
			phandle = <0xc0>;
		};

		watchdog@ff120000 {
			compatible = "xlnx,versal-wwdt-1.0\0xlnx,versal-wwdt";
			status = "okay";
			reg = <0x00 0xff120000 0x00 0x10000>;
			interrupt-parent = <0x3e>;
			interrupt-names = "wdt\0wwdt_reset_pending\0gwdt\0gwdt_reset_pending";
			interrupts = <0x00 0x31 0x01 0x00 0x45 0x01 0x00 0x46 0x04 0x00 0x47 0x04>;
			timeout-sec = <0x1e>;
			clocks = <0x72 0x52>;
			power-domains = <0x71 0x18224028>;
			xlnx,winwdt-example = <0x01>;
			xlnx,ip-name = "psv_wwdt";
			xlnx,wdt-clk-freq-hz = <0x5f5e100>;
			phandle = <0x57>;
		};

		edac@f2014050 {
			compatible = "xlnx,versal-xilsem-edac";
			status = "disabled";
			reg = <0x00 0xf2014050 0x00 0xc4>;
			phandle = <0xc1>;
		};

		pmcdma@f11c0000 {
			status = "okay";
			compatible = "xlnx,zynqmp-csudma-1.0";
			interrupt-parent = <0x3e>;
			interrupts = <0x00 0x83 0x04>;
			reg = <0x00 0xf11c0000 0x00 0x10000>;
			xlnx,dma-type = <0x01>;
			xlnx,ip-name = "psv_pmc_dma";
			phandle = <0x2a>;
		};

		pmcdma@f11d0000 {
			status = "okay";
			compatible = "xlnx,zynqmp-csudma-1.0";
			interrupt-parent = <0x3e>;
			interrupts = <0x00 0x84 0x04>;
			reg = <0x00 0xf11d0000 0x00 0x10000>;
			xlnx,dma-type = <0x02>;
			xlnx,ip-name = "psv_pmc_dma";
			phandle = <0x2b>;
		};

		coresight@f0800000 {
			compatible = "xlnx,coresight-1.0";
			status = "okay";
			reg = <0x00 0xf0800000 0x00 0x10000>;
			xlnx,ip-name = "psv_coresight";
			phandle = <0x0d>;
		};

		versal_cips_0_pspmc_0_psv_cpm@0 {
			compatible = "xlnx,psv-cpm-1.0";
			status = "okay";
			xlnx,ip-name = "psv_cpm";
			reg = <0x00 0xfc000000 0x00 0x1000000>;
			phandle = <0x3f>;
		};

		interrupt-controller@f9000000 {
			phandle = <0x3e>;
			xlnx,ip-name = "psv_acpu_gic";
			xlnx,apu-gic-its-ctl = <0xf9020000>;
			status = "okay";
			interrupts = <0x01 0x09 0x04>;
			interrupt-parent = <0x3e>;
			interrupt-controller;
			reg = <0x00 0xf9000000 0x00 0x80000 0x00 0xf9080000 0x00 0x80000>;
			ranges;
			#size-cells = <0x02>;
			#address-cells = <0x02>;
			#interrupt-cells = <0x03>;
			compatible = "arm,gic-v3";

			msi-controller@f9020000 {
				phandle = <0x05>;
				reg = <0x00 0xf9020000 0x00 0x20000>;
				#msi-cells = <0x01>;
				msi-controller;
				status = "okay";
				compatible = "arm,gic-v3-its";
			};
		};
	};

	indirect-bus@1 {
		compatible = "indirect-bus";
		#address-cells = <0x02>;
		#size-cells = <0x02>;
		phandle = <0x12e>;

		xppu@ff990000 {
			compatible = "xlnx,xppu";
			#firewall-cells = <0x00>;
			reg = <0x00 0xff990000 0x00 0x2000>;
			status = "okay";
			xlnx,ip-name = "psv_lpd_xppu";
			phandle = <0x5f>;
		};

		xppu@f1310000 {
			compatible = "xlnx,xppu";
			#firewall-cells = <0x00>;
			reg = <0x00 0xf1310000 0x00 0x2000>;
			status = "okay";
			xlnx,ip-name = "psv_pmc_xppu";
			phandle = <0x3b>;
		};

		xppu@f1300000 {
			compatible = "xlnx,xppu";
			#firewall-cells = <0x00>;
			reg = <0x00 0xf1300000 0x00 0x2000>;
			status = "okay";
			xlnx,ip-name = "psv_pmc_xppu_npi";
			phandle = <0x3a>;
		};
	};

	indirect-bus@2 {
		compatible = "indirect-bus";
		#address-cells = <0x02>;
		#size-cells = <0x02>;
		phandle = <0x12f>;

		xmpu@fd390000 {
			compatible = "xlnx,xmpu";
			#firewall-cells = <0x00>;
			reg = <0x00 0xfd390000 0x00 0x1000>;
			status = "okay";
			xlnx,ip-name = "psv_fpd_slave_xmpu";
			phandle = <0x44>;
		};

		xmpu@f12f0000 {
			compatible = "xlnx,xmpu";
			#firewall-cells = <0x00>;
			reg = <0x00 0xf12f0000 0x00 0x1000>;
			status = "okay";
			xlnx,ip-name = "psv_pmc_xmpu";
			phandle = <0x39>;
		};

		xmpu@ff980000 {
			compatible = "xlnx,xmpu";
			#firewall-cells = <0x00>;
			reg = <0x00 0xff980000 0x00 0x1000>;
			status = "okay";
			xlnx,ip-name = "psv_ocm_xmpu";
			phandle = <0x5e>;
		};

		xmpu@f6390000 {
			compatible = "xlnx,xmpu";
			#firewall-cells = <0x00>;
			reg = <0x00 0xf6390000 0x00 0x1000>;
			status = "disabled";
			phandle = <0x132>;
		};

		xmpu@f6500000 {
			compatible = "xlnx,xmpu";
			#firewall-cells = <0x00>;
			reg = <0x00 0xf6500000 0x00 0x1000>;
			status = "disabled";
			phandle = <0x133>;
		};
	};

	pl_alt_ref_clk {
		bootph-all;
		compatible = "fixed-clock";
		#clock-cells = <0x00>;
		clock-frequency = <0x1fca055>;
		phandle = <0x97>;
	};

	ref_clk {
		bootph-all;
		compatible = "fixed-clock";
		#clock-cells = <0x00>;
		clock-frequency = <0x1fca055>;
		phandle = <0x96>;
	};

	can0_clk {
		#clock-cells = <0x00>;
		compatible = "fixed-factor-clock";
		clocks = <0x72 0x60>;
		clock-div = <0x02>;
		clock-mult = <0x01>;
		phandle = <0x90>;
	};

	can1_clk {
		#clock-cells = <0x00>;
		compatible = "fixed-factor-clock";
		clocks = <0x72 0x61>;
		clock-div = <0x02>;
		clock-mult = <0x01>;
		phandle = <0x91>;
	};

	firmware {

		versal-firmware {
			compatible = "xlnx,versal-firmware";
			interrupt-parent = <0x3e>;
			bootph-all;
			method = "smc";
			#power-domain-cells = <0x01>;
			phandle = <0x71>;

			clock-controller {
				bootph-all;
				#clock-cells = <0x01>;
				compatible = "xlnx,versal-clk";
				clocks = <0x96 0x97>;
				clock-names = "ref_clk\0pl_alt_ref_clk";
				phandle = <0x72>;
			};

			zynqmp-power {
				compatible = "xlnx,zynqmp-power";
				phandle = <0x134>;
			};

			reset-controller {
				compatible = "xlnx,versal-reset";
				#reset-cells = <0x01>;
				phandle = <0x93>;
			};

			pinctrl {
				compatible = "xlnx,versal-pinctrl";
				phandle = <0x135>;
			};

			versal-sec-cfg {
				compatible = "xlnx,versal-sec-cfg";
				#address-cells = <0x01>;
				#size-cells = <0x01>;
				phandle = <0x136>;

				bbram-zeroize@4 {
					reg = <0x04 0x04>;
					phandle = <0x137>;
				};

				bbram-key@10 {
					reg = <0x10 0x20>;
					phandle = <0x138>;
				};

				bbram-usr@30 {
					reg = <0x30 0x04>;
					phandle = <0x139>;
				};

				bbram-lock@48 {
					reg = <0x48 0x04>;
					phandle = <0x13a>;
				};

				user-key@110 {
					reg = <0x110 0x20>;
					phandle = <0x13b>;
				};

				user-key@130 {
					reg = <0x130 0x20>;
					phandle = <0x13c>;
				};

				user-key@150 {
					reg = <0x150 0x20>;
					phandle = <0x13d>;
				};

				user-key@170 {
					reg = <0x170 0x20>;
					phandle = <0x13e>;
				};

				user-key@190 {
					reg = <0x190 0x20>;
					phandle = <0x13f>;
				};

				user-key@1b0 {
					reg = <0x1b0 0x20>;
					phandle = <0x140>;
				};

				user-key@1d0 {
					reg = <0x1d0 0x20>;
					phandle = <0x141>;
				};

				user-key@1f0 {
					reg = <0x1f0 0x20>;
					phandle = <0x142>;
				};
			};
		};
	};

	amba_pl {
		ranges;
		compatible = "simple-bus";
		#address-cells = <0x02>;
		#size-cells = <0x02>;
		firmware-name = "project_1.pdi";
		phandle = <0x143>;
	};

	memory@00000000 {
		compatible = "xlnx,axi-noc-1.1";
		xlnx,ip-name = "axi_noc";
		device_type = "memory";
		reg = <0x00 0x00 0x00 0x80000000 0x08 0x00 0x07 0x80000000>;
		memory_type = "memory";
		phandle = <0x03>;
	};

	memory@4000000000 {
		compatible = "xlnx,axi-noc-1.1";
		xlnx,ip-name = "axi_noc";
		device_type = "memory";
		reg = <0x40 0x00 0x00 0x40000000 0x40 0x40000000 0x00 0x40000000 0x40 0x80000000 0x00 0x40000000 0x40 0xc0000000 0x00 0x40000000 0x41 0x00 0x00 0x40000000 0x41 0x40000000 0x00 0x40000000 0x41 0x80000000 0x00 0x40000000 0x41 0xc0000000 0x00 0x40000000 0x42 0x00 0x00 0x40000000 0x42 0x40000000 0x00 0x40000000 0x42 0x80000000 0x00 0x40000000 0x42 0xc0000000 0x00 0x40000000 0x43 0x00 0x00 0x40000000 0x43 0x40000000 0x00 0x40000000 0x43 0x80000000 0x00 0x40000000 0x43 0xc0000000 0x00 0x40000000 0x44 0x00 0x00 0x40000000 0x44 0x40000000 0x00 0x40000000 0x44 0x80000000 0x00 0x40000000 0x44 0xc0000000 0x00 0x40000000 0x45 0x00 0x00 0x40000000 0x45 0x40000000 0x00 0x40000000 0x45 0x80000000 0x00 0x40000000 0x45 0xc0000000 0x00 0x40000000 0x46 0x00 0x00 0x40000000 0x46 0x40000000 0x00 0x40000000 0x46 0x80000000 0x00 0x40000000 0x46 0xc0000000 0x00 0x40000000 0x47 0x00 0x00 0x40000000 0x47 0x40000000 0x00 0x40000000 0x47 0x80000000 0x00 0x40000000 0x47 0xc0000000 0x00 0x40000000>;
		memory_type = "memory";
		phandle = <0x04>;
	};

	chosen {
		stdout-path = "serial0:115200n8";
		bootargs = "console=ttyAMA0 earlycon=pl011,mmio32,0xFF000000,115200n8 root=/dev/ram0 rw init_fatal_sh=1";
	};

	aliases {
		serial0 = "/axi/serial@ff000000";
		serial1 = "/axi/coresight@f0800000";
		i2c0 = "/axi/i2c@ff020000";
		i2c1 = "/axi/i2c@ff030000";
		ethernet0 = "/axi/ethernet@ff0c0000";
		serial2 = "/dcc";
		mmc0 = "/axi/mmc@f1050000";
		spi0 = "/axi/spi@f1010000";
		usb0 = "/axi/usb@ff9d0000";
		rtc0 = "/axi/rtc@f12a0000";
	};

	__symbols__ {
		cpus_a72 = "/cpus-a72@0";
		psv_cortexa72_0 = "/cpus-a72@0/cpu@0";
		psv_cortexa72_1 = "/cpus-a72@0/cpu@1";
		CPU_SLEEP_0 = "/cpus-a72@0/idle-states/cpu-sleep-0";
		cpu_opp_table = "/opp-table-cpu";
		dcc = "/dcc";
		fpga = "/fpga-region";
		psci = "/psci";
		timer = "/timer";
		versal_fpga = "/versal-fpga";
		sensor0 = "/versal-thermal-sensor";
		versal_thermal = "/thermal-zones/versal-thermal";
		temp_alert = "/thermal-zones/versal-thermal/trips/temp-alert";
		ot_crit = "/thermal-zones/versal-thermal/trips/ot-crit";
		amba_apu = "/apu-bus";
		gic_its = "/axi/interrupt-controller@f9000000/msi-controller@f9020000";
		amba = "/axi";
		imux = "/axi/interrupt-multiplex";
		can0 = "/axi/can@ff060000";
		can1 = "/axi/can@ff070000";
		cci = "/axi/cci@fd000000";
		cci_pmu = "/axi/cci@fd000000/pmu@10000";
		lpd_dma_chan0 = "/axi/dma-controller@ffa80000";
		lpd_dma_chan1 = "/axi/dma-controller@ffa90000";
		lpd_dma_chan2 = "/axi/dma-controller@ffaa0000";
		lpd_dma_chan3 = "/axi/dma-controller@ffab0000";
		lpd_dma_chan4 = "/axi/dma-controller@ffac0000";
		lpd_dma_chan5 = "/axi/dma-controller@ffad0000";
		lpd_dma_chan6 = "/axi/dma-controller@ffae0000";
		lpd_dma_chan7 = "/axi/dma-controller@ffaf0000";
		gem0 = "/axi/ethernet@ff0c0000";
		mdio = "/axi/ethernet@ff0c0000/mdio";
		phy1 = "/axi/ethernet@ff0c0000/mdio/ethernet-phy@1";
		gem1 = "/axi/ethernet@ff0d0000";
		gpio0 = "/axi/gpio@ff0b0000";
		gpio1 = "/axi/gpio@f1020000";
		i2c0 = "/axi/i2c@ff020000";
		i2c1 = "/axi/i2c@ff030000";
		i2c2 = "/axi/i2c@f1000000";
		mc2 = "/axi/memory-controller@f6430000";
		mc3 = "/axi/memory-controller@f65a0000";
		ocm = "/axi/memory-controller@ff960000";
		rtc = "/axi/rtc@f12a0000";
		sdhci0 = "/axi/mmc@f1040000";
		sdhci1 = "/axi/mmc@f1050000";
		serial0 = "/axi/serial@ff000000";
		serial1 = "/axi/serial@ff010000";
		smmu = "/axi/iommu@fd800000";
		ospi = "/axi/spi@f1010000";
		qspi = "/axi/spi@f1030000";
		spi0 = "/axi/spi@ff040000";
		spi1 = "/axi/spi@ff050000";
		sysmon0 = "/axi/sysmon@f1270000";
		sysmon1 = "/axi/sysmon@109270000";
		sysmon2 = "/axi/sysmon@111270000";
		sysmon3 = "/axi/sysmon@119270000";
		ttc0 = "/axi/timer@ff0e0000";
		ttc1 = "/axi/timer@ff0f0000";
		ttc2 = "/axi/timer@ff100000";
		ttc3 = "/axi/timer@ff110000";
		usb0 = "/axi/usb@ff9d0000";
		dwc3_0 = "/axi/usb@ff9d0000/usb@fe200000";
		cpm_pciea = "/axi/pci@fca10000";
		pcie_intc_0 = "/axi/pci@fca10000/interrupt-controller";
		cpm5_pcie = "/axi/pcie@fcdd0000";
		pcie_intc_2 = "/axi/pcie@fcdd0000/interrupt-controller";
		watchdog = "/axi/watchdog@fd4d0000";
		watchdog1 = "/axi/watchdog@ff120000";
		xilsem_edac = "/axi/edac@f2014050";
		dma0 = "/axi/pmcdma@f11c0000";
		dma1 = "/axi/pmcdma@f11d0000";
		coresight = "/axi/coresight@f0800000";
		versal_cips_0_pspmc_0_psv_cpm = "/axi/versal_cips_0_pspmc_0_psv_cpm@0";
		amba_xppu = "/indirect-bus@1";
		lpd_xppu = "/indirect-bus@1/xppu@ff990000";
		pmc_xppu = "/indirect-bus@1/xppu@f1310000";
		pmc_xppu_npi = "/indirect-bus@1/xppu@f1300000";
		amba_xmpu = "/indirect-bus@2";
		fpd_xmpu = "/indirect-bus@2/xmpu@fd390000";
		pmc_xmpu = "/indirect-bus@2/xmpu@f12f0000";
		ocm_xmpu = "/indirect-bus@2/xmpu@ff980000";
		ddrmc_xmpu_2 = "/indirect-bus@2/xmpu@f6390000";
		ddrmc_xmpu_3 = "/indirect-bus@2/xmpu@f6500000";
		pl_alt_ref_clk = "/pl_alt_ref_clk";
		ref_clk = "/ref_clk";
		can0_clk = "/can0_clk";
		can1_clk = "/can1_clk";
		versal_firmware = "/firmware/versal-firmware";
		versal_clk = "/firmware/versal-firmware/clock-controller";
		zynqmp_power = "/firmware/versal-firmware/zynqmp-power";
		versal_reset = "/firmware/versal-firmware/reset-controller";
		pinctrl0 = "/firmware/versal-firmware/pinctrl";
		versal_sec_cfg = "/firmware/versal-firmware/versal-sec-cfg";
		bbram_zeroize = "/firmware/versal-firmware/versal-sec-cfg/bbram-zeroize@4";
		bbram_key = "/firmware/versal-firmware/versal-sec-cfg/bbram-key@10";
		bbram_usr = "/firmware/versal-firmware/versal-sec-cfg/bbram-usr@30";
		bbram_lock = "/firmware/versal-firmware/versal-sec-cfg/bbram-lock@48";
		user_key0 = "/firmware/versal-firmware/versal-sec-cfg/user-key@110";
		user_key1 = "/firmware/versal-firmware/versal-sec-cfg/user-key@130";
		user_key2 = "/firmware/versal-firmware/versal-sec-cfg/user-key@150";
		user_key3 = "/firmware/versal-firmware/versal-sec-cfg/user-key@170";
		user_key4 = "/firmware/versal-firmware/versal-sec-cfg/user-key@190";
		user_key5 = "/firmware/versal-firmware/versal-sec-cfg/user-key@1b0";
		user_key6 = "/firmware/versal-firmware/versal-sec-cfg/user-key@1d0";
		user_key7 = "/firmware/versal-firmware/versal-sec-cfg/user-key@1f0";
		amba_pl = "/amba_pl";
		axi_noc_0_ddr_memory = "/memory@00000000";
		axi_noc_0_hbm_memory = "/memory@4000000000";
		gic = "/axi/interrupt-controller@f9000000";
		flash0 = "/axi/spi@f1010000/flash@0";
	};
};
